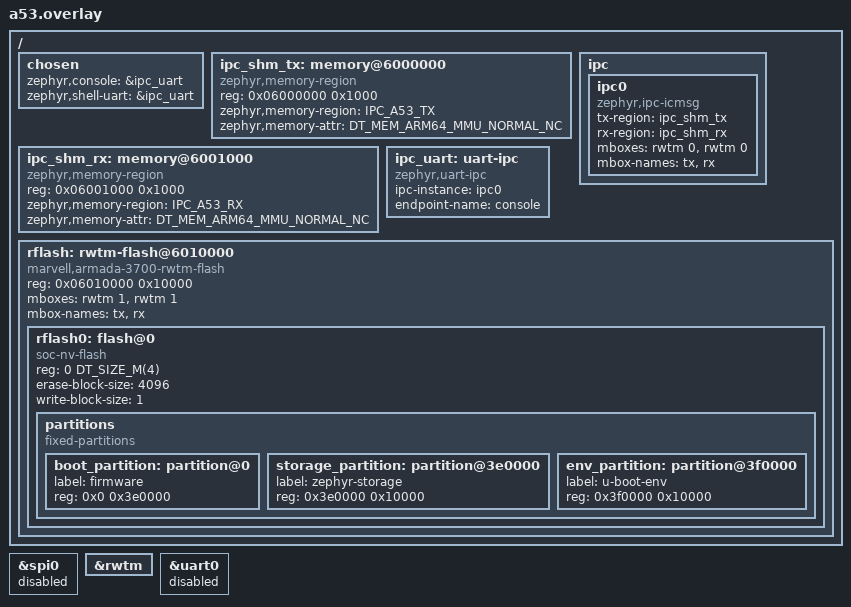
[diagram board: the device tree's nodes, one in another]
/*
 * Copyright (c) 2026 Jiri Kastner
 * SPDX-License-Identifier: Apache-2.0
 *
 * A53 console through the CM3: UART0 is the CM3's, the console is an
 * icmsg endpoint in DDR at 0x06000000 (CM3 0x66000000), the rWTM
 * mailbox rings the doorbells. Uncached on the A53: the CM3 is not
 * behind the CCI.
 */

#include <mem.h>
#include <zephyr/dt-bindings/memory-attr/memory-attr-arm64.h>

/ {
	chosen {
		zephyr,console = &ipc_uart;
		zephyr,shell-uart = &ipc_uart;
	};

	ipc_shm_tx: memory@6000000 {
		compatible = "zephyr,memory-region", "mmio-sram";
		reg = <0x06000000 0x1000>;
		zephyr,memory-region = "IPC_A53_TX";
		zephyr,memory-attr = <DT_MEM_ARM64_MMU_NORMAL_NC>;
	};

	ipc_shm_rx: memory@6001000 {
		compatible = "zephyr,memory-region", "mmio-sram";
		reg = <0x06001000 0x1000>;
		zephyr,memory-region = "IPC_A53_RX";
		zephyr,memory-attr = <DT_MEM_ARM64_MMU_NORMAL_NC>;
	};

	ipc {
		ipc0: ipc0 {
			compatible = "zephyr,ipc-icmsg";
			tx-region = <&ipc_shm_tx>;
			rx-region = <&ipc_shm_rx>;
			mboxes = <&rwtm 0>, <&rwtm 0>;
			mbox-names = "tx", "rx";
			status = "okay";
		};
	};

	ipc_uart: uart-ipc {
		compatible = "zephyr,uart-ipc";
		ipc-instance = "ipc0";
		endpoint-name = "console";
		status = "okay";
	};
};

/* the SPI NOR belongs to the CM3 */
/delete-node/ &spi_nor;

&spi0 {
	status = "disabled";
};

/ {
	rflash: rwtm-flash@6010000 {
		compatible = "marvell,armada-3700-rwtm-flash";
		reg = <0x06010000 0x10000>;
		mboxes = <&rwtm 1>, <&rwtm 1>;
		mbox-names = "tx", "rx";
		#address-cells = <1>;
		#size-cells = <1>;

		rflash0: flash@0 {
			compatible = "soc-nv-flash";
			reg = <0 DT_SIZE_M(4)>;
			erase-block-size = <4096>;
			write-block-size = <1>;

			partitions {
				compatible = "fixed-partitions";
				#address-cells = <1>;
				#size-cells = <1>;

				/* written only by the CM3, as a whole checked image */
				boot_partition: partition@0 {
					label = "firmware";
					reg = <0x0 0x3e0000>;
				};

				storage_partition: partition@3e0000 {
					label = "zephyr-storage";
					reg = <0x3e0000 0x10000>;
				};

				env_partition: partition@3f0000 {
					label = "u-boot-env";
					reg = <0x3f0000 0x10000>;
				};
			};
		};
	};
};

&rwtm {
	status = "okay";
};

&uart0 {
	status = "disabled";
};
